# STM32L4Q5ZGT6P register map
File version: 1.0
Registers are 32-bit, access not given, reset 0x0 unless marked. A register's access mark holds for its fields unless they carry their own. Offsets are from the block's base; [hi:lo] are bit positions; {n}, {i} and the like mark numbered series.

## ADC1
Base 0x50040000
Same registers: ADC2 0x50040100
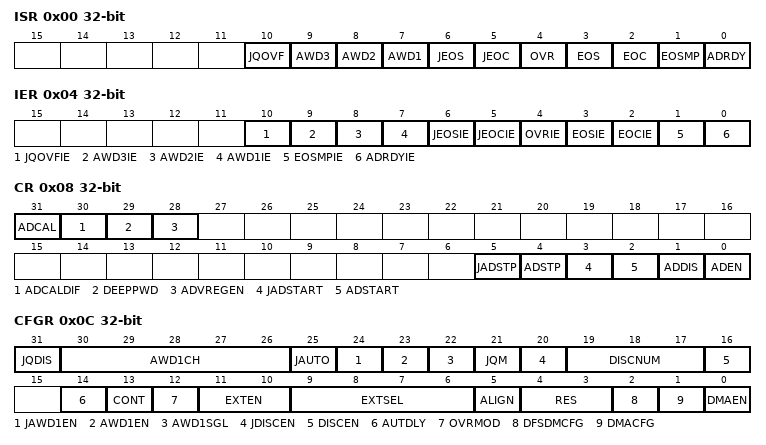
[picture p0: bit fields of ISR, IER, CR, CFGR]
0x00 ISR
  [10] JQOVF, [9] AWD3, [8] AWD2, [7] AWD1, [6] JEOS, [5] JEOC, [4] OVR, [3] EOS, [2] EOC, [1] EOSMP, [0] ADRDY
0x04 IER
  [10] JQOVFIE, [9] AWD3IE, [8] AWD2IE, [7] AWD1IE, [6] JEOSIE, [5] JEOCIE, [4] OVRIE, [3] EOSIE, [2] EOCIE, [1] EOSMPIE, [0] ADRDYIE
0x08 CR
  [31] ADCAL, [30] ADCALDIF, [29] DEEPPWD, [28] ADVREGEN, [5] JADSTP, [4] ADSTP, [3] JADSTART, [2] ADSTART, [1] ADDIS, [0] ADEN
0x0C CFGR
  [31] JQDIS, [30:26] AWD1CH, [25] JAUTO, [24] JAWD1EN, [23] AWD1EN, [22] AWD1SGL, [21] JQM, [20] JDISCEN, [19:17] DISCNUM, [16] DISCEN, [14] AUTDLY, [13] CONT, [12] OVRMOD, [11:10] EXTEN, [9:6] EXTSEL, [5] ALIGN, [4:3] RES, [2] DFSDMCFG, [1] DMACFG, [0] DMAEN
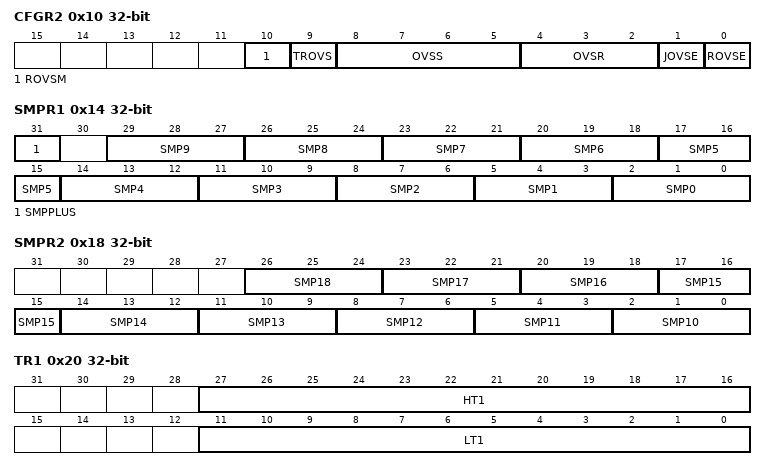
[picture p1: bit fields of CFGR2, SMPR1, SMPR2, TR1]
0x10 CFGR2
  [10] ROVSM, [9] TROVS, [8:5] OVSS, [4:2] OVSR, [1] JOVSE, [0] ROVSE
0x14 SMPR1
  [31] SMPPLUS, [3n+2:3n] SMP{n} (n=0..9)
0x18 SMPR2
  [3n-28:3n-30] SMP{n} (n=10..18)
0x20 TR1
  [27:16] HT1, [11:0] LT1
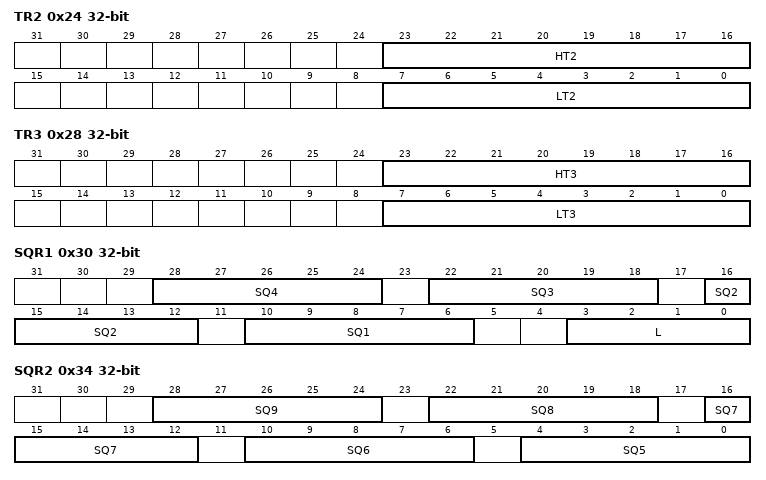
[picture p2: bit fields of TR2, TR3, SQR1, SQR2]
0x24 TR2
  [23:16] HT2, [7:0] LT2
0x28 TR3
  [23:16] HT3, [7:0] LT3
0x30 SQR1
  [6n+4:6n] SQ{n} (n=1..4), [3:0] L
0x34 SQR2
  [6n-26:6n-30] SQ{n} (n=5..9)
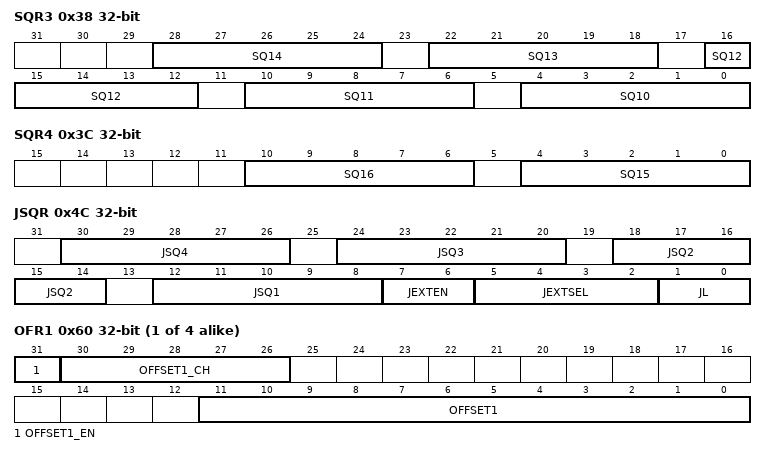
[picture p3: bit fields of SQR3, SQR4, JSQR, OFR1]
0x38 SQR3
  [6n-56:6n-60] SQ{n} (n=10..14)
0x3C SQR4
  [10:6] SQ16, [4:0] SQ15
0x40 DR
  [15:0] RDATA
0x4C JSQR
  [6n+6:6n+2] JSQ{n} (n=1..4), [7:6] JEXTEN, [5:2] JEXTSEL, [1:0] JL
{0x5C+4i} OFR{i} (i=1..4)
  [31] OFFSET{i}_EN, [30:26] OFFSET{i}_CH, [11:0] OFFSET{i}
{0x7C+4i} JDR{i} (i=1..4)
  [15:0] JDATA
0xA0 AWD2CR
  [18:0] AWD2CH
0xA4 AWD3CR
  [18:0] AWD3CH
0xB0 DIFSEL
  [18:0] DIFSEL
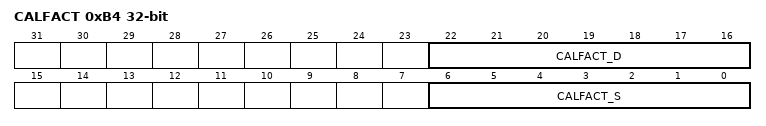
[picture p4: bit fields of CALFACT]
0xB4 CALFACT
  [22:16] CALFACT_D, [6:0] CALFACT_S

## ADC12_COMMON
Base 0x50040300
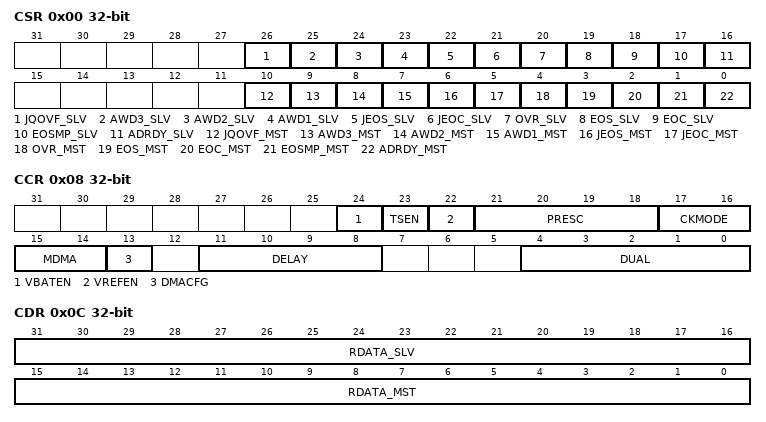
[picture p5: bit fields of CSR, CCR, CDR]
0x00 CSR
  [26] JQOVF_SLV, [25] AWD3_SLV, [24] AWD2_SLV, [23] AWD1_SLV, [22] JEOS_SLV, [21] JEOC_SLV, [20] OVR_SLV, [19] EOS_SLV, [18] EOC_SLV, [17] EOSMP_SLV, [16] ADRDY_SLV, [10] JQOVF_MST, [9] AWD3_MST, [8] AWD2_MST, [7] AWD1_MST, [6] JEOS_MST, [5] JEOC_MST, [4] OVR_MST, [3] EOS_MST, [2] EOC_MST, [1] EOSMP_MST, [0] ADRDY_MST
0x08 CCR
  [24] VBATEN, [23] TSEN, [22] VREFEN, [21:18] PRESC, [17:16] CKMODE, [15:14] MDMA, [13] DMACFG, [11:8] DELAY, [4:0] DUAL
0x0C CDR
  [31:16] RDATA_SLV, [15:0] RDATA_MST

## DCMI
Base 0x50050000
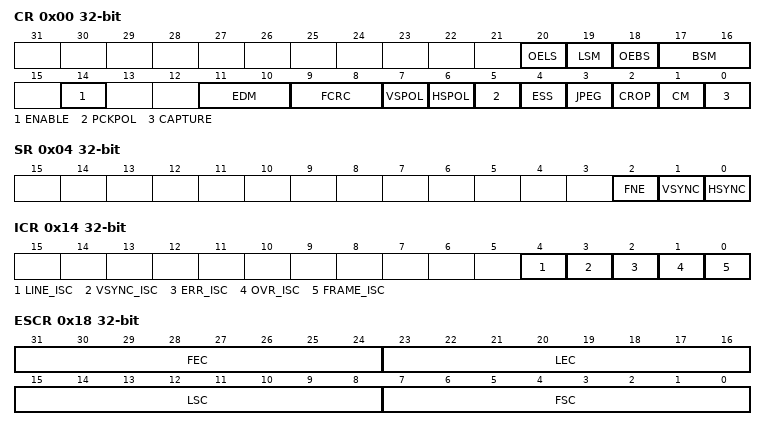
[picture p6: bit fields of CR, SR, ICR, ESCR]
0x00 CR
  [20] OELS, [19] LSM, [18] OEBS, [17:16] BSM, [14] ENABLE, [11:10] EDM, [9:8] FCRC, [7] VSPOL, [6] HSPOL, [5] PCKPOL, [4] ESS, [3] JPEG, [2] CROP, [1] CM, [0] CAPTURE
0x04 SR
  [2] FNE, [1] VSYNC, [0] HSYNC
0x08 RISR
0x0C IER
  [4] LINE_IE, [3] VSYNC_IE, [2] ERR_IE, [1] OVR_IE, [4:0] INT_IE
0x10 MISR
0x14 ICR
  [4] LINE_ISC, [3] VSYNC_ISC, [2] ERR_ISC, [1] OVR_ISC, [0] FRAME_ISC
0x18 ESCR
  [31:24] FEC, [23:16] LEC, [15:8] LSC, [7:0] FSC
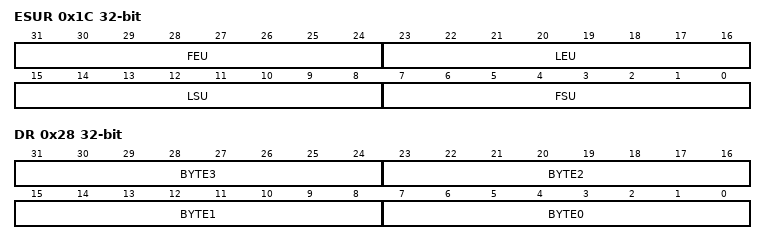
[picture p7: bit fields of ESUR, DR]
0x1C ESUR
  [31:24] FEU, [23:16] LEU, [15:8] LSU, [7:0] FSU
0x20 CWSTRTR
0x24 CWSIZER
0x28 DR
  [8n+7:8n] BYTE{n} (n=0..3)

## PSSI
Base 0x50050400
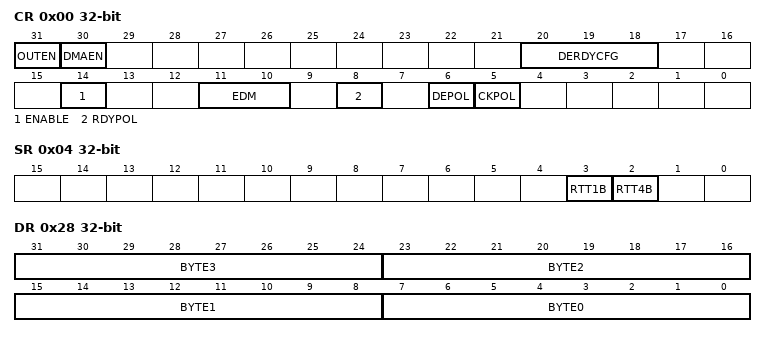
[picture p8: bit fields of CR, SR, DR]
0x00 CR
  [31] OUTEN, [30] DMAEN, [20:18] DERDYCFG, [14] ENABLE, [11:10] EDM, [8] RDYPOL, [6] DEPOL, [5] CKPOL
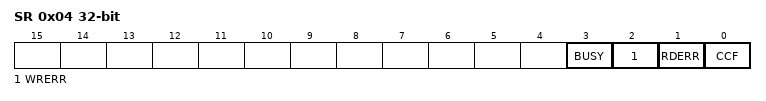
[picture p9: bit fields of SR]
0x04 SR
  [3] RTT1B, [2] RTT4B
0x08 RIS
  [1] OVR_RIS
0x0C IER
  [1] OVR_IE
0x10 MIS
  [1] OVR_MIS
0x14 ICR
  [1] OVR_ISC
0x28 DR
  [8n+7:8n] BYTE{n} (n=0..3)
0x3F0 HWCFGR
0x3F4 VERR
0x3F8 IPIDR
0x3FC SIDR

## AES
Base 0x50060000
0x00 CR
  [23:20] NPBLB, [18] KEYSIZE, [14:13] GCMPH, [12] DMAOUTEN, [11] DMAINEN, [10] ERRIE, [9] CCFIE, [8] ERRC, [7] CCFC, [16:5] CHMOD, [4:3] MODE, [2:1] DATATYPE, [0] EN
0x04 SR
  [3] BUSY, [2] WRERR, [1] RDERR, [0] CCF
0x08 DINR
0x0C DOUTR
{0x10+4i} KEYR{i} (i=0..3)
{0x20+4i} IVR{i} (i=0..3)
{0x20+4i} KEYR{i} (i=4..7)
{0x40+4i} SUSP{i}R (i=0..7)

## HASH
Base 0x50060400
0x00 CR
  [16] LKEY, [13] MDMAT, [12] DINNE, [11:8] NBW, [18:7] ALGO, [6] MODE, [5:4] DATATYPE, [3] DMAE, [2] INIT
0x04 DIN
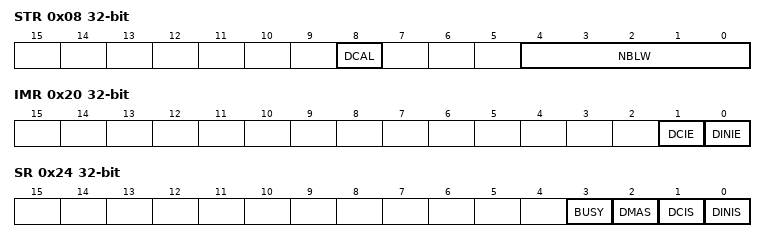
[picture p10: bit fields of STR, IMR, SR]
0x08 STR
  [8] DCAL, [4:0] NBLW
0x0C HR.0
0x10 HR.1
0x14 HR.2
0x18 HR.3
0x1C HR.4
0x20 IMR
  [1] DCIE, [0] DINIE
0x24 SR
  [3] BUSY, [2] DMAS, [1] DCIS, [0] DINIS
0xF8 CSR.0
0xFC CSR.1
0x100 CSR.2
0x104 CSR.3
0x108 CSR.4
0x10C CSR.5
0x110 CSR.6
0x114 CSR.7
0x118 CSR.8
0x11C CSR.9
0x120 CSR.10
0x124 CSR.11
0x128 CSR.12
0x12C CSR.13
0x130 CSR.14
0x134 CSR.15
0x138 CSR.16
0x13C CSR.17
0x140 CSR.18
0x144 CSR.19
0x148 CSR.20
0x14C CSR.21
0x150 CSR.22
0x154 CSR.23
0x158 CSR.24
0x15C CSR.25
0x160 CSR.26
0x164 CSR.27
0x168 CSR.28
0x16C CSR.29
0x170 CSR.30
0x174 CSR.31
0x178 CSR.32
0x17C CSR.33
0x180 CSR.34
0x184 CSR.35
0x188 CSR.36
0x18C CSR.37
0x190 CSR.38
0x194 CSR.39
0x198 CSR.40
0x19C CSR.41
0x1A0 CSR.42
0x1A4 CSR.43
0x1A8 CSR.44
0x1AC CSR.45
0x1B0 CSR.46
0x1B4 CSR.47
0x1B8 CSR.48
0x1BC CSR.49
0x1C0 CSR.50
0x1C4 CSR.51
0x1C8 CSR.52
0x1CC CSR.53
